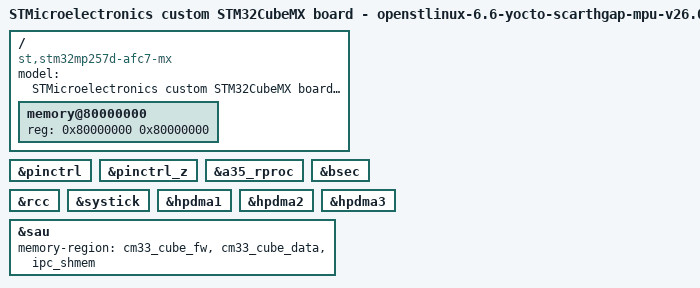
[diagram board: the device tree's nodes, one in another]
// SPDX-License-Identifier: (GPL-2.0-only OR BSD-3-Clause)
/*
 * Copyright (C) 2026, STMicroelectronics - All Rights Reserved
 * Author: STM32CubeMX code generation for STMicroelectronics.
 */

/* For more information on Device Tree configuration, please refer to
 * https://wiki.st.com/stm32mpu/wiki/Category:Device_tree_configuration
 */
/dts-v1/;
#include <dt-bindings/clock/stm32mp25-clksrc.h>
#include <dt-bindings/pinctrl/stm32-pinfunc.h>
#include <dt-bindings/rif/stm32mp25-rif.h>
#include <dt-bindings/rif/stm32mp25-rifsc.h>
#include <dt-bindings/rif/stm32mp2-risaf.h>
#include <dt-bindings/rif/stm32mp25-risab.h>
#include "stm32mp257.dtsi"
#include "stm32mp25xd.dtsi"
#include "stm32mp257d-afc7-mx-rcc.dtsi"
#include "stm32mp257d-afc7-mx-resmem.dtsi"
#include "stm32mp257d-afc7-mx-rif.dtsi"
#include "stm32mp25xxak-pinctrl.dtsi"

/* USER CODE BEGIN includes */
/* USER CODE END includes */

/ {
	model = "STMicroelectronics custom STM32CubeMX board - openstlinux-6.6-yocto-scarthgap-mpu-v26.02.18";
	compatible = "st,stm32mp257d-afc7-mx", "st,stm32mp257";

	memory@80000000 {
		device_type = "memory";
		reg = <0x80000000 0x80000000>;

		/* USER CODE BEGIN memory */
		/* USER CODE END memory */
	};

	/* USER CODE BEGIN root */
	/* USER CODE END root */

}; /*root*/

&pinctrl {

	/* USER CODE BEGIN pinctrl */
	/* USER CODE END pinctrl */
};

&pinctrl_z {

	/* USER CODE BEGIN pinctrl_z */
	/* USER CODE END pinctrl_z */
};

&a35_rproc {
	status = "okay";

	/* USER CODE BEGIN a35_rproc */
	/* USER CODE END a35_rproc */
};

&bsec {
	status = "okay";

	/* USER CODE BEGIN bsec */
	/* USER CODE END bsec */
};

&rcc {
	status = "okay";

	/* USER CODE BEGIN rcc */
	/* USER CODE END rcc */
};

&systick {
	status = "okay";

	/* USER CODE BEGIN systick */
	/* USER CODE END systick */
};

&hpdma1 {
	status = "okay";

	/* USER CODE BEGIN hpdma1 */
	/* USER CODE END hpdma1 */
};

&hpdma2 {
	status = "okay";

	/* USER CODE BEGIN hpdma2 */
    /* USER CODE END hpdma2 */
};

&hpdma3 {
	status = "okay";

    /* USER CODE BEGIN hpdma3 */
    /* USER CODE END hpdma3 */
};

&sau {
	memory-region = <&cm33_cube_fw>, <&cm33_cube_data>, <&ipc_shmem>;
	status = "okay";

	/* USER CODE BEGIN sau */
	/* USER CODE END sau */
};

/* USER CODE BEGIN addons */
/* USER CODE END addons */

